VERSION "FA20DIT LF75404S (clean-room, our research notes)"

NS_ :

BS_:

BU_: ECM VDC TCM METER BCM OTHER

BO_ 208 RX_0D0: 8 VDC
 SG_ vdc0d0_b6 : 48|8@1+ (1,0) [0|0] "signed" ECM
 SG_ vdc0d0_b7 : 56|8@1+ (1,0) [0|0] "signed" ECM

BO_ 209 RX_0D1: 4 VDC
 SG_ vehicle_speed : 0|16@1+ (0.05625,0) [0|0] "km/h" ECM
 SG_ brake_pressure : 16|8@1+ (1,0) [0|0] "raw" ECM

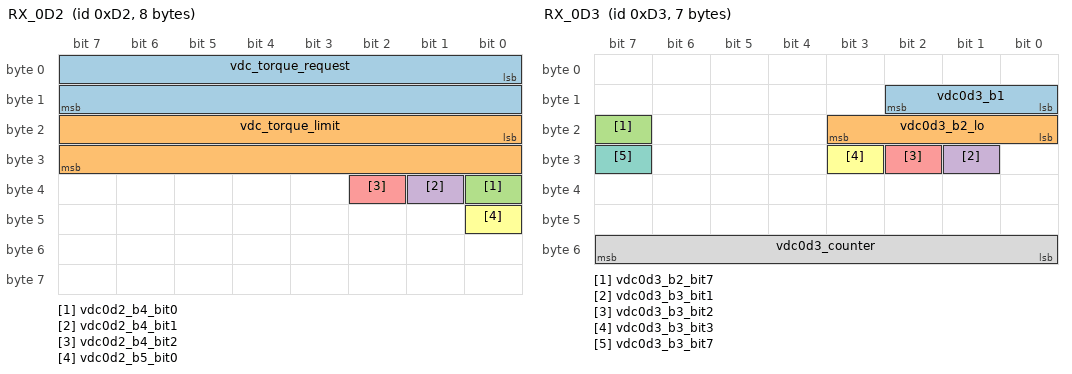
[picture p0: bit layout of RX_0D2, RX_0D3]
BO_ 210 RX_0D2: 8 VDC
 SG_ vdc_torque_request : 0|16@1+ (0.1,-1000) [0|0] "Nm" ECM
 SG_ vdc_torque_limit : 16|16@1+ (0.1,-1000) [0|0] "Nm" ECM
 SG_ vdc0d2_b4_bit0 : 32|1@1+ (1,0) [0|0] "raw" ECM
 SG_ vdc0d2_b4_bit1 : 33|1@1+ (1,0) [0|0] "raw" ECM
 SG_ vdc0d2_b4_bit2 : 34|1@1+ (1,0) [0|0] "raw" ECM
 SG_ vdc0d2_b5_bit0 : 40|1@1+ (1,0) [0|0] "raw" ECM

BO_ 211 RX_0D3: 7 VDC
 SG_ vdc0d3_b1 : 8|3@1+ (1,0) [0|0] "raw" ECM
 SG_ vdc0d3_b2_lo : 16|4@1+ (1,0) [0|0] "raw" ECM
 SG_ vdc0d3_b2_bit7 : 23|1@1+ (1,0) [0|0] "raw" ECM
 SG_ vdc0d3_b3_bit1 : 25|1@1+ (1,0) [0|0] "raw" ECM
 SG_ vdc0d3_b3_bit2 : 26|1@1+ (1,0) [0|0] "raw" ECM
 SG_ vdc0d3_b3_bit3 : 27|1@1+ (1,0) [0|0] "raw" ECM
 SG_ vdc0d3_b3_bit7 : 31|1@1+ (1,0) [0|0] "raw" ECM
 SG_ vdc0d3_counter : 48|8@1+ (1,0) [0|0] "raw" ECM

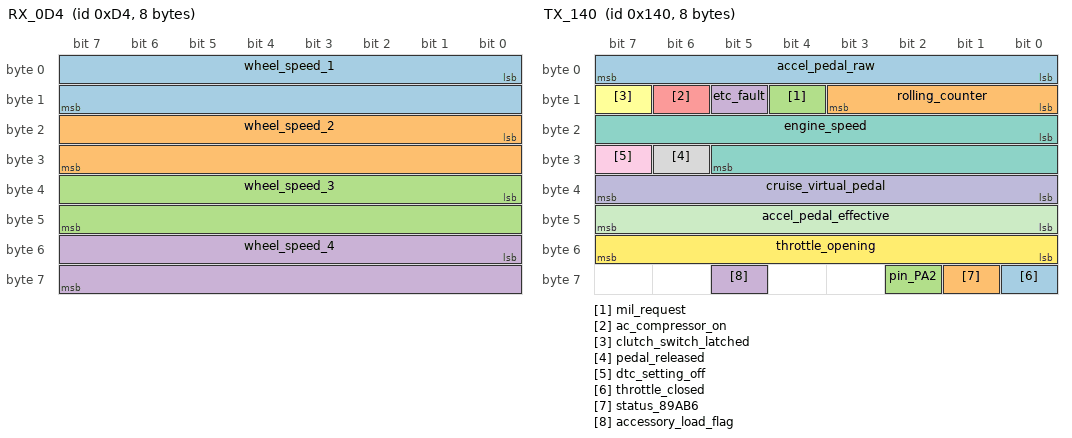
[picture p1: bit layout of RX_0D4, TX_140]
BO_ 212 RX_0D4: 8 VDC
 SG_ wheel_speed_1 : 0|16@1+ (0.05625,0) [0|0] "km/h" ECM
 SG_ wheel_speed_2 : 16|16@1+ (0.05625,0) [0|0] "km/h" ECM
 SG_ wheel_speed_3 : 32|16@1+ (0.05625,0) [0|0] "km/h" ECM
 SG_ wheel_speed_4 : 48|16@1+ (0.05625,0) [0|0] "km/h" ECM

BO_ 320 TX_140: 8 ECM
 SG_ accel_pedal_raw : 0|8@1+ (0.39215686274509803,0) [0|0] "%" Vector__XXX
 SG_ rolling_counter : 8|4@1+ (1,0) [0|0] "count" Vector__XXX
 SG_ mil_request : 12|1@1+ (1,0) [0|0] "flag" Vector__XXX
 SG_ etc_fault : 13|1@1+ (1,0) [0|0] "flag" Vector__XXX
 SG_ ac_compressor_on : 14|1@1+ (1,0) [0|0] "flag" Vector__XXX
 SG_ clutch_switch_latched : 15|1@1+ (1,0) [0|0] "flag" Vector__XXX
 SG_ engine_speed : 16|14@1+ (1,0) [0|0] "rpm" Vector__XXX
 SG_ pedal_released : 30|1@1+ (1,0) [0|0] "flag" Vector__XXX
 SG_ dtc_setting_off : 31|1@1+ (1,0) [0|0] "flag" Vector__XXX
 SG_ cruise_virtual_pedal : 32|8@1+ (0.39215686274509803,0) [0|0] "%" Vector__XXX
 SG_ accel_pedal_effective : 40|8@1+ (0.39215686274509803,0) [0|0] "%" Vector__XXX
 SG_ throttle_opening : 48|8@1+ (0.39215686274509803,0) [0|0] "%" Vector__XXX
 SG_ throttle_closed : 56|1@1+ (1,0) [0|0] "flag" Vector__XXX
 SG_ status_89AB6 : 57|1@1+ (1,0) [0|0] "flag" Vector__XXX
 SG_ pin_PA2 : 58|1@1+ (1,0) [0|0] "flag" Vector__XXX
 SG_ accessory_load_flag : 61|1@1+ (1,0) [0|0] "flag" Vector__XXX

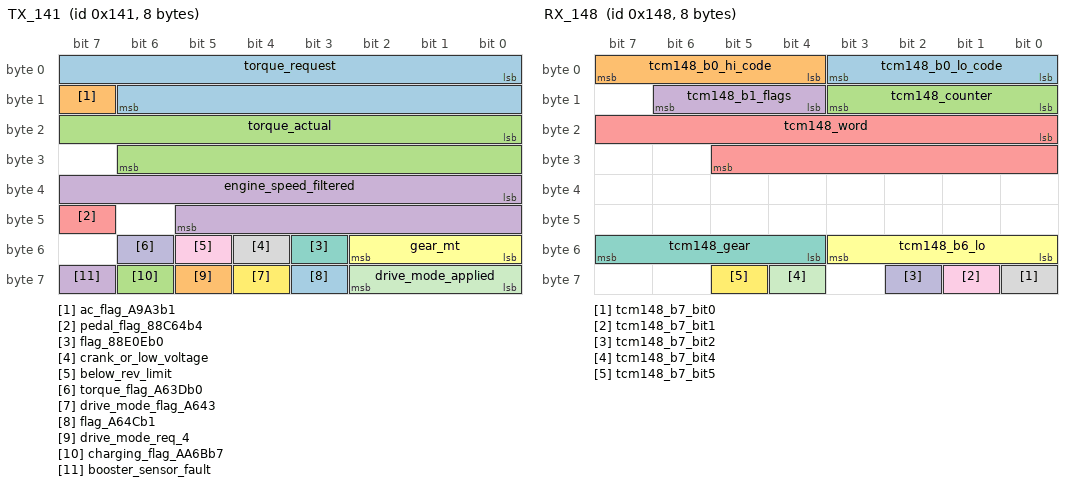
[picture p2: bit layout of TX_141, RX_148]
BO_ 321 TX_141: 8 ECM
 SG_ torque_request : 0|15@1+ (0.1,-1000) [0|0] "Nm" Vector__XXX
 SG_ ac_flag_A9A3b1 : 15|1@1+ (1,0) [0|0] "flag" Vector__XXX
 SG_ torque_actual : 16|15@1+ (0.1,-1000) [0|0] "Nm" Vector__XXX
 SG_ engine_speed_filtered : 32|14@1+ (1,0) [0|0] "rpm" Vector__XXX
 SG_ pedal_flag_88C64b4 : 47|1@1+ (1,0) [0|0] "flag" Vector__XXX
 SG_ gear_mt : 48|3@1+ (1,0) [0|0] "gear" Vector__XXX
 SG_ flag_88E0Eb0 : 51|1@1+ (1,0) [0|0] "flag" Vector__XXX
 SG_ crank_or_low_voltage : 52|1@1+ (1,0) [0|0] "flag" Vector__XXX
 SG_ below_rev_limit : 53|1@1+ (1,0) [0|0] "flag" Vector__XXX
 SG_ torque_flag_A63Db0 : 54|1@1+ (1,0) [0|0] "flag" Vector__XXX
 SG_ drive_mode_applied : 56|3@1+ (1,0) [0|0] "code" Vector__XXX
 SG_ drive_mode_flag_A643 : 60|1@1+ (1,0) [0|0] "flag" Vector__XXX
 SG_ flag_A64Cb1 : 59|1@1+ (1,0) [0|0] "flag" Vector__XXX
 SG_ drive_mode_req_4 : 61|1@1+ (1,0) [0|0] "flag" Vector__XXX
 SG_ charging_flag_AA6Bb7 : 62|1@1+ (1,0) [0|0] "flag" Vector__XXX
 SG_ booster_sensor_fault : 63|1@1+ (1,0) [0|0] "flag" Vector__XXX

BO_ 324 TX_144: 8 ECM
 SG_ cruise_switch_flag : 2|1@1+ (1,0) [0|0] "flag" Vector__XXX
 SG_ cruise_switch_code : 3|3@1+ (1,0) [0|0] "code" Vector__XXX
 SG_ cruise_meter_flag_b5 : 6|1@1+ (1,0) [0|0] "flag" Vector__XXX
 SG_ cruise_meter_flag_b6 : 7|1@1+ (1,0) [0|0] "flag" Vector__XXX
 SG_ drive_cycle_done : 9|1@1+ (1,0) [0|0] "flag" Vector__XXX
 SG_ torque_monitor_AC77b0 : 11|1@1+ (1,0) [0|0] "flag" Vector__XXX
 SG_ cruise_switch_taps : 12|4@1+ (1,0) [0|0] "bits" Vector__XXX
 SG_ max_available_torque : 16|8@1+ (1.6,0) [0|0] "Nm" Vector__XXX
 SG_ start_counter : 24|8@1+ (1,0) [0|0] "count" Vector__XXX
 SG_ warmup_counter : 32|8@1+ (1,0) [0|0] "count" Vector__XXX
 SG_ coding_byte : 40|8@1+ (1,0) [0|0] "raw" Vector__XXX
 SG_ cruise_standby : 48|1@1+ (1,0) [0|0] "flag" Vector__XXX
 SG_ cruise_active : 49|1@1+ (1,0) [0|0] "flag" Vector__XXX
 SG_ cruise_override : 50|1@1+ (1,0) [0|0] "flag" Vector__XXX
 SG_ pin_PA15 : 51|1@1+ (1,0) [0|0] "flag" Vector__XXX
 SG_ can_fault_latch : 52|1@1+ (1,0) [0|0] "flag" Vector__XXX
 SG_ cruise_unavailable : 53|1@1+ (1,0) [0|0] "flag" Vector__XXX
 SG_ vdc_flag_inverted : 54|1@1+ (1,0) [0|0] "flag" Vector__XXX
 SG_ mt_coding : 55|1@1+ (1,0) [0|0] "flag" Vector__XXX
 SG_ drive_mode_state : 56|1@1+ (1,0) [0|0] "flag" Vector__XXX
 SG_ drive_mode_requested : 57|3@1+ (1,0) [0|0] "code" Vector__XXX
 SG_ cal_57ABC_b2 : 62|1@1+ (1,0) [0|0] "flag" Vector__XXX

BO_ 328 RX_148: 8 TCM
 SG_ tcm148_b0_lo_code : 0|4@1+ (1,0) [0|0] "raw" ECM
 SG_ tcm148_b0_hi_code : 4|4@1+ (1,0) [0|0] "raw" ECM
 SG_ tcm148_counter : 8|4@1+ (1,0) [0|0] "raw" ECM
 SG_ tcm148_b1_flags : 12|3@1+ (1,0) [0|0] "raw" ECM
 SG_ tcm148_word : 16|14@1+ (1,0) [0|0] "raw" ECM
 SG_ tcm148_b6_lo : 48|4@1+ (1,0) [0|0] "raw" ECM
 SG_ tcm148_gear : 52|4@1+ (1,0) [0|0] "gear code" ECM
 SG_ tcm148_b7_bit0 : 56|1@1+ (1,0) [0|0] "raw" ECM
 SG_ tcm148_b7_bit1 : 57|1@1+ (1,0) [0|0] "raw" ECM
 SG_ tcm148_b7_bit2 : 58|1@1+ (1,0) [0|0] "raw" ECM
 SG_ tcm148_b7_bit4 : 60|1@1+ (1,0) [0|0] "raw" ECM
 SG_ tcm148_b7_bit5 : 61|1@1+ (1,0) [0|0] "raw" ECM

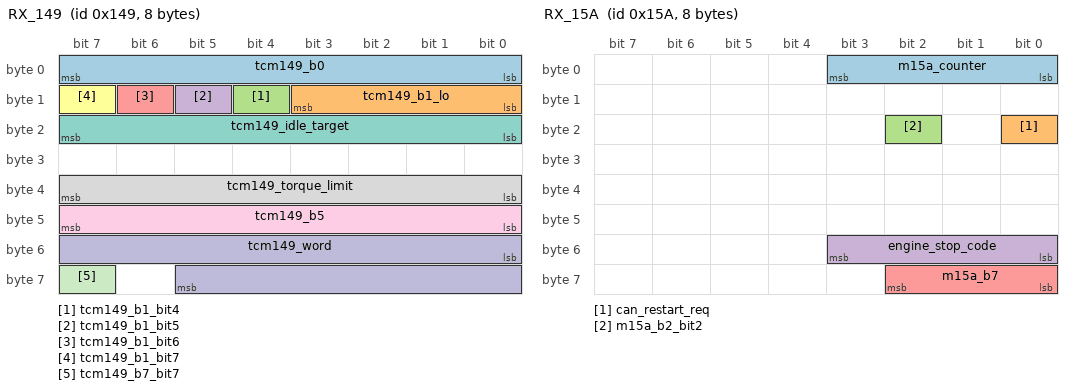
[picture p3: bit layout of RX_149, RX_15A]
BO_ 329 RX_149: 8 TCM
 SG_ tcm149_b0 : 0|8@1+ (1,0) [0|0] "raw" ECM
 SG_ tcm149_b1_lo : 8|4@1+ (1,0) [0|0] "raw" ECM
 SG_ tcm149_b1_bit4 : 12|1@1+ (1,0) [0|0] "raw" ECM
 SG_ tcm149_b1_bit5 : 13|1@1+ (1,0) [0|0] "raw" ECM
 SG_ tcm149_b1_bit6 : 14|1@1+ (1,0) [0|0] "raw" ECM
 SG_ tcm149_b1_bit7 : 15|1@1+ (1,0) [0|0] "raw" ECM
 SG_ tcm149_idle_target : 16|8@1+ (8,0) [0|0] "rpm" ECM
 SG_ tcm149_torque_limit : 32|8@1+ (2,0) [0|0] "Nm" ECM
 SG_ tcm149_b5 : 40|8@1+ (1,0) [0|0] "raw" ECM
 SG_ tcm149_word : 48|14@1+ (1,0) [0|0] "raw" ECM
 SG_ tcm149_b7_bit7 : 63|1@1+ (1,0) [0|0] "raw" ECM

BO_ 338 RX_152: 8 BCM
 SG_ bcm152_b1_bit0 : 8|1@1+ (1,0) [0|0] "raw" ECM
 SG_ bcm152_b1_bit1 : 9|1@1+ (1,0) [0|0] "raw" ECM
 SG_ bcm152_b1_bit2 : 10|1@1+ (1,0) [0|0] "raw" ECM
 SG_ bcm152_b1_bit3 : 11|1@1+ (1,0) [0|0] "raw" ECM
 SG_ bcm152_counter : 12|4@1+ (1,0) [0|0] "raw" ECM
 SG_ bcm152_b6_bit0 : 48|1@1+ (1,0) [0|0] "raw" ECM
 SG_ bcm152_b6_bit2 : 50|1@1+ (1,0) [0|0] "raw" ECM
 SG_ bcm152_b6_bit3 : 51|1@1+ (1,0) [0|0] "raw" ECM
 SG_ bcm152_b6_bit4 : 52|1@1+ (1,0) [0|0] "raw" ECM
 SG_ bcm152_b6_bit5 : 53|1@1+ (1,0) [0|0] "raw" ECM
 SG_ bcm152_b6_hi : 54|2@1+ (1,0) [0|0] "raw" ECM
 SG_ bcm152_b7_bit1 : 57|1@1+ (1,0) [0|0] "raw" ECM
 SG_ bcm152_b7_bit2 : 58|1@1+ (1,0) [0|0] "raw" ECM
 SG_ bcm152_b7_bit3 : 59|1@1+ (1,0) [0|0] "raw" ECM
 SG_ bcm152_b7_bit4 : 60|1@1+ (1,0) [0|0] "raw" ECM
 SG_ bcm152_b7_bit5 : 61|1@1+ (1,0) [0|0] "raw" ECM
 SG_ bcm152_b7_bit6 : 62|1@1+ (1,0) [0|0] "raw" ECM
 SG_ bcm152_b7_bit7 : 63|1@1+ (1,0) [0|0] "raw" ECM

BO_ 346 RX_15A: 8 OTHER
 SG_ m15a_counter : 0|4@1+ (1,0) [0|0] "raw" ECM
 SG_ can_restart_req : 16|1@1+ (1,0) [0|0] "raw" ECM
 SG_ m15a_b2_bit2 : 18|1@1+ (1,0) [0|0] "raw" ECM
 SG_ engine_stop_code : 48|4@1+ (1,0) [0|0] "raw" ECM
 SG_ m15a_b7 : 56|3@1+ (1,0) [0|0] "raw" ECM

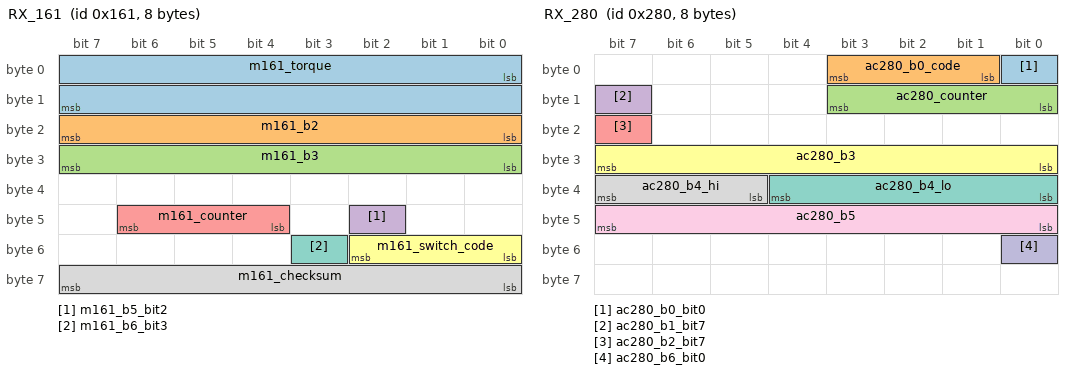
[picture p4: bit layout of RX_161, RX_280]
BO_ 353 RX_161: 8 METER
 SG_ m161_torque : 0|16@1+ (0.1,-1000) [0|0] "Nm" ECM
 SG_ m161_b2 : 16|8@1+ (1,0) [0|0] "raw" ECM
 SG_ m161_b3 : 24|8@1+ (1,0) [0|0] "raw" ECM
 SG_ m161_b5_bit2 : 42|1@1+ (1,0) [0|0] "raw" ECM
 SG_ m161_counter : 44|3@1+ (1,0) [0|0] "raw" ECM
 SG_ m161_switch_code : 48|3@1+ (1,0) [0|0] "raw" ECM
 SG_ m161_b6_bit3 : 51|1@1+ (1,0) [0|0] "raw" ECM
 SG_ m161_checksum : 56|8@1+ (1,0) [0|0] "raw" ECM

BO_ 392 RX_188: 8 OTHER
 SG_ m188_counter : 17|3@1+ (1,0) [0|0] "raw" ECM
 SG_ m188_code : 32|3@1+ (1,0) [0|0] "raw" ECM

BO_ 640 RX_280: 8 OTHER
 SG_ ac280_b0_bit0 : 0|1@1+ (1,0) [0|0] "raw" ECM
 SG_ ac280_b0_code : 1|3@1+ (1,0) [0|0] "raw" ECM
 SG_ ac280_counter : 8|4@1+ (1,0) [0|0] "raw" ECM
 SG_ ac280_b1_bit7 : 15|1@1+ (1,0) [0|0] "raw" ECM
 SG_ ac280_b2_bit7 : 23|1@1+ (1,0) [0|0] "raw" ECM
 SG_ ac280_b3 : 24|8@1+ (1,0) [0|0] "raw" ECM
 SG_ ac280_b4_lo : 32|5@1+ (1,0) [0|0] "raw" ECM
 SG_ ac280_b4_hi : 37|3@1+ (1,0) [0|0] "raw" ECM
 SG_ ac280_b5 : 40|8@1+ (1,0) [0|0] "%" ECM
 SG_ ac280_b6_bit0 : 48|1@1+ (1,0) [0|0] "raw" ECM

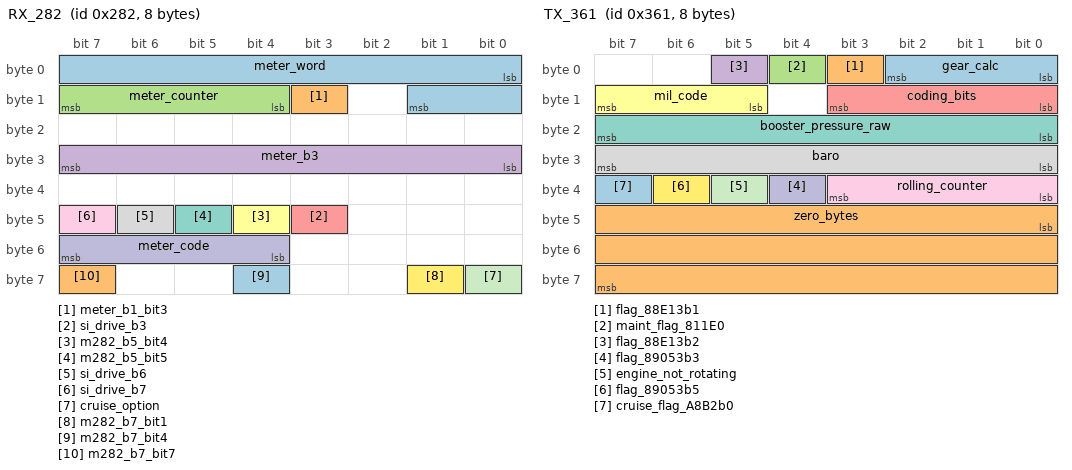
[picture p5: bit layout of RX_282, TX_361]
BO_ 642 RX_282: 8 METER
 SG_ meter_word : 0|10@1+ (1,0) [0|0] "raw" ECM
 SG_ meter_b1_bit3 : 11|1@1+ (1,0) [0|0] "raw" ECM
 SG_ meter_counter : 12|4@1+ (1,0) [0|0] "raw" ECM
 SG_ meter_b3 : 24|8@1+ (1,0) [0|0] "raw" ECM
 SG_ si_drive_b3 : 43|1@1+ (1,0) [0|0] "raw" ECM
 SG_ m282_b5_bit4 : 44|1@1+ (1,0) [0|0] "raw" ECM
 SG_ m282_b5_bit5 : 45|1@1+ (1,0) [0|0] "raw" ECM
 SG_ si_drive_b6 : 46|1@1+ (1,0) [0|0] "raw" ECM
 SG_ si_drive_b7 : 47|1@1+ (1,0) [0|0] "raw" ECM
 SG_ meter_code : 52|4@1+ (1,0) [0|0] "raw" ECM
 SG_ cruise_option : 56|1@1+ (1,0) [0|0] "raw" ECM
 SG_ m282_b7_bit1 : 57|1@1+ (1,0) [0|0] "raw" ECM
 SG_ m282_b7_bit4 : 60|1@1+ (1,0) [0|0] "raw" ECM
 SG_ m282_b7_bit7 : 63|1@1+ (1,0) [0|0] "raw" ECM

BO_ 864 TX_360: 8 ECM
 SG_ fuel_flow : 0|16@1+ (0.001,0) [0|0] "unit not settled" Vector__XXX
 SG_ oil_temp : 16|8@1+ (1,-40) [0|0] "degC" Vector__XXX
 SG_ coolant_temp : 24|8@1+ (1,-40) [0|0] "degC" Vector__XXX
 SG_ map : 32|8@1+ (2,0) [0|0] "kPa abs" Vector__XXX
 SG_ flag_888A7b1 : 40|1@1+ (1,0) [0|0] "flag" Vector__XXX
 SG_ drive_mode_req_bits : 41|3@1+ (1,0) [0|0] "code" Vector__XXX
 SG_ cruise_lamp_main : 44|1@1+ (1,0) [0|0] "flag" Vector__XXX
 SG_ cruise_lamp_set : 45|1@1+ (1,0) [0|0] "flag" Vector__XXX
 SG_ engine_warm_latch : 46|1@1+ (1,0) [0|0] "flag" Vector__XXX
 SG_ flag_ACECb4 : 47|1@1+ (1,0) [0|0] "flag" Vector__XXX
 SG_ flag_88E14b0 : 48|1@1+ (1,0) [0|0] "flag" Vector__XXX
 SG_ elec_load_flag : 49|1@1+ (1,0) [0|0] "flag" Vector__XXX
 SG_ flag_88E14b4 : 50|1@1+ (1,0) [0|0] "flag" Vector__XXX
 SG_ flag_8889Eb5 : 51|1@1+ (1,0) [0|0] "flag" Vector__XXX
 SG_ rad_fan_1 : 52|1@1+ (1,0) [0|0] "flag" Vector__XXX
 SG_ rad_fan_2 : 53|1@1+ (1,0) [0|0] "flag" Vector__XXX
 SG_ ac_switch_PA8 : 54|1@1+ (1,0) [0|0] "flag" Vector__XXX
 SG_ ac_request : 55|1@1+ (1,0) [0|0] "flag" Vector__XXX
 SG_ cruise_set_speed : 56|8@1+ (1,0) [0|0] "km/h or mph" Vector__XXX

BO_ 865 TX_361: 8 ECM
 SG_ gear_calc : 0|3@1+ (1,0) [0|0] "gear" Vector__XXX
 SG_ flag_88E13b1 : 3|1@1+ (1,0) [0|0] "flag" Vector__XXX
 SG_ maint_flag_811E0 : 4|1@1+ (1,0) [0|0] "flag" Vector__XXX
 SG_ flag_88E13b2 : 5|1@1+ (1,0) [0|0] "flag" Vector__XXX
 SG_ coding_bits : 8|4@1+ (1,0) [0|0] "raw" Vector__XXX
 SG_ mil_code : 13|3@1+ (1,0) [0|0] "code" Vector__XXX
 SG_ booster_pressure_raw : 16|8@1+ (256,0) [0|0] "ADC raw" Vector__XXX
 SG_ baro : 24|8@1+ (0.4,13.2) [0|0] "kPa abs" Vector__XXX
 SG_ rolling_counter : 32|4@1+ (1,0) [0|0] "count" Vector__XXX
 SG_ flag_89053b3 : 36|1@1+ (1,0) [0|0] "flag" Vector__XXX
 SG_ engine_not_rotating : 37|1@1+ (1,0) [0|0] "flag" Vector__XXX
 SG_ flag_89053b5 : 38|1@1+ (1,0) [0|0] "flag" Vector__XXX
 SG_ cruise_flag_A8B2b0 : 39|1@1+ (1,0) [0|0] "flag" Vector__XXX
 SG_ zero_bytes : 40|24@1+ (1,0) [0|0] "-" Vector__XXX

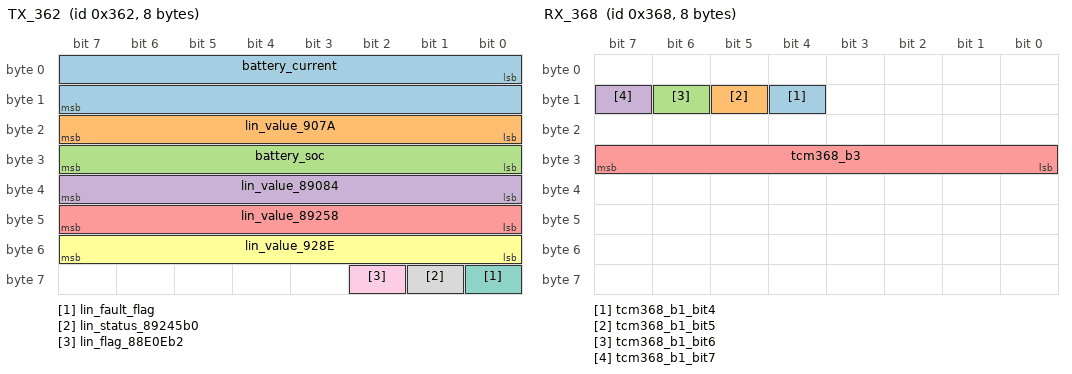
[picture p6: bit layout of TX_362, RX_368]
BO_ 866 TX_362: 8 ECM
 SG_ battery_current : 0|16@1+ (0.004,-125) [0|0] "A" Vector__XXX
 SG_ lin_value_907A : 16|8@1+ (1,0) [0|0] "raw" Vector__XXX
 SG_ battery_soc : 24|8@1+ (0.5,0) [0|0] "%" Vector__XXX
 SG_ lin_value_89084 : 32|8@1+ (8,0) [0|0] "raw" Vector__XXX
 SG_ lin_value_89258 : 40|8@1+ (8,0) [0|0] "raw" Vector__XXX
 SG_ lin_value_928E : 48|8@1+ (64,0) [0|0] "raw" Vector__XXX
 SG_ lin_fault_flag : 56|1@1+ (1,0) [0|0] "flag" Vector__XXX
 SG_ lin_status_89245b0 : 57|1@1+ (1,0) [0|0] "flag" Vector__XXX
 SG_ lin_flag_88E0Eb2 : 58|1@1+ (1,0) [0|0] "flag" Vector__XXX

BO_ 872 RX_368: 8 TCM
 SG_ tcm368_b1_bit4 : 12|1@1+ (1,0) [0|0] "raw" ECM
 SG_ tcm368_b1_bit5 : 13|1@1+ (1,0) [0|0] "raw" ECM
 SG_ tcm368_b1_bit6 : 14|1@1+ (1,0) [0|0] "raw" ECM
 SG_ tcm368_b1_bit7 : 15|1@1+ (1,0) [0|0] "raw" ECM
 SG_ tcm368_b3 : 24|8@1+ (1,0) [0|0] "raw" ECM

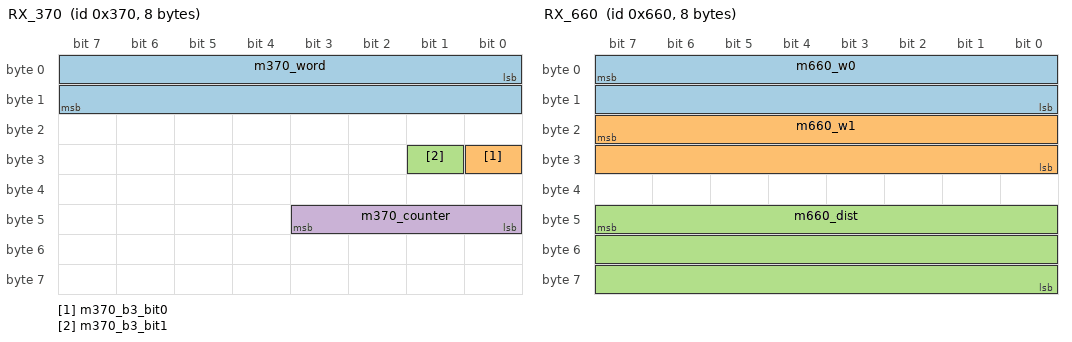
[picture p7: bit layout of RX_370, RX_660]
BO_ 880 RX_370: 8 OTHER
 SG_ m370_word : 0|16@1+ (1,0) [0|0] "raw" ECM
 SG_ m370_b3_bit0 : 24|1@1+ (1,0) [0|0] "raw" ECM
 SG_ m370_b3_bit1 : 25|1@1+ (1,0) [0|0] "raw" ECM
 SG_ m370_counter : 40|4@1+ (1,0) [0|0] "raw" ECM

BO_ 882 RX_372: 8 OTHER
 SG_ m372_counter : 12|4@1+ (1,0) [0|0] "raw" ECM
 SG_ m372_code : 21|3@1+ (1,0) [0|0] "raw" ECM

BO_ 977 RX_3D1: 8 METER
 SG_ ambient_temp_raw : 0|13@1+ (1,0) [0|0] "raw" ECM

BO_ 1632 RX_660: 8 BCM
 SG_ m660_w0 : 7|16@0+ (1,0) [0|0] "raw" ECM
 SG_ m660_w1 : 23|16@0+ (1,0) [0|0] "raw" ECM
 SG_ m660_dist : 47|24@0+ (1,0) [0|0] "raw" ECM

BO_ 1905 TX_771: 8 ECM
 SG_ periodic_did : 0|8@1+ (1,0) [0|0] "DID low byte (0xF2xx)" Vector__XXX
 SG_ did_data : 8|56@1+ (1,0) [0|0] "raw" Vector__XXX

BO_ 2015 RX_7DF: 8 OTHER

BO_ 2016 RX_7E0: 8 OTHER

BO_ 2024 TX_7E8: 8 ECM

CM_ SG_ 208 vdc0d0_b6 "RAM FFF88DF7; inferred; -> 0x11637C (gated by cal 0x364F3 b6) -> FFF8A8D1 / B406 / B452; meaning not determined";
CM_ SG_ 208 vdc0d0_b7 "RAM FFF88DF8; inferred; as byte 6";
CM_ BO_ 208 "VDC (FFF88DD8, U0122); timeout 30 ms";
CM_ SG_ 209 vehicle_speed "RAM FFF88E18; read; -> 0x118D9C -> FFF8B4C2 -> 0x06C21C -> FFF88BE8 (ECU vehicle speed, x17.78) and FFF99835 (km/h); fallback 10 km/h on VDC fault";
CM_ SG_ 209 brake_pressure "RAM FFF88DF9; inferred; brake override 0x181B38 (FFF8AC94), 0x0DE0E0, 0x0EE338, 0x111AB8";
CM_ BO_ 209 "VDC (FFF88DD8); timeout 30 ms";
CM_ SG_ 210 vdc_torque_request "RAM FFF888B4; inferred; -> 0x116264 -> FFF8B470 (applied only while FFF8A89F b2 = byte4 bit1 and value > 10000 and FFF886AB b5); fallback 10000 (0 Nm)";
CM_ SG_ 210 vdc_torque_limit "RAM FFF888B6; inferred; -> 0x117778 -> FFF8B47C/B464/B466 (torque module 0x0BE694, monitors 0x189DF0/0x1A8D6C); fallback 0x3700 (+408 Nm)";
CM_ SG_ 210 vdc0d2_b4_bit0 "RAM FFF88B94 b0; read; 0x117778 select, 0x11B594 -> FFF8A89F b3";
CM_ SG_ 210 vdc0d2_b4_bit1 "RAM FFF88B93 b1; read; torque-request enable (0x11B814 -> FFF8A89F b2)";
CM_ SG_ 210 vdc0d2_b4_bit2 "RAM FFF88B93 b2; read; 0x1191D4 -> FFF8A89F b1";
CM_ SG_ 210 vdc0d2_b5_bit0 "RAM FFF88B93 b3; read; 0x115438 (SI-Drive arbitration), 0x0BE694";
CM_ BO_ 210 "VDC (FFF88DD8); timeout 30 ms";
CM_ SG_ 211 vdc0d3_b1 "RAM FFF88B95 b0-2; read; b0/b1 -> 0x11BBB4 -> FFF8A898, FFF8A8A1 b7";
CM_ SG_ 211 vdc0d3_b2_lo "RAM FFF88B96 b0-3; read; 0x1191D4, 0x11A0C4 (FFF8A8A2 b7), 0x11FA38";
CM_ SG_ 211 vdc0d3_b2_bit7 "RAM FFF88B97 b6; read; brake override validity 0x181978";
CM_ SG_ 211 vdc0d3_b3_bit1 "RAM FFF88B94 b7; read; 0x113894 (FFF8A8D1 path)";
CM_ SG_ 211 vdc0d3_b3_bit2 "RAM FFF88B94 b2; read; speed/VDC status: 0x06EDDC, cruise speed 0x16C2D0";
CM_ SG_ 211 vdc0d3_b3_bit3 "RAM FFF88B97 b3; read; 0x115438 SI-Drive, brake override 0x181978";
CM_ SG_ 211 vdc0d3_b3_bit7 "RAM FFF88B97 b7; read; 0x11BD48 -> FFF8A89F b0; FFF9BA24..26 delay line (0x0B5758)";
CM_ SG_ 211 vdc0d3_counter "RAM FFF888BB; read; rolling counter; U0416 if unchanged 200 passes";
CM_ BO_ 211 "VDC (FFF88DD8; U0416 = this counter frozen); timeout 30 ms; counter byte6 (whole byte, frozen check)";
CM_ SG_ 212 wheel_speed_1 "RAM FFF88B98; inferred; -> FFF8B4C0";
CM_ SG_ 212 wheel_speed_2 "RAM FFF88B9A; inferred; -> FFF8B4C4";
CM_ SG_ 212 wheel_speed_3 "RAM FFF88B9C; inferred; -> FFF8B4C6";
CM_ SG_ 212 wheel_speed_4 "RAM FFF88B9E; inferred; -> FFF8B4C8";
CM_ BO_ 212 "VDC (FFF88DD8); timeout 30 ms";
CM_ SG_ 320 accel_pedal_raw "RAM FFF8A8D8 <- hi(FFF88EE8); read/inferred; Accelerator pedal, channel-1 position through Accelerator Pedal Scaling (0..65535) high byte; fallback cal 0x573C4 on pedal fault";
CM_ SG_ 320 rolling_counter "RAM FFF8A893; read; 4-bit rolling counter 0..15, +1 per 10 ms (= per frame); 0..7 in variants 0";
CM_ SG_ 320 mil_request "RAM FFF88E13 b0; read/inferred; MIL requested: FFF99809 b3 (DTC confirmed, MIL on) OR FFF88E69 b1 (flashing-MIL DTC)";
CM_ SG_ 320 etc_fault "RAM FFF88EDA b4; read/inferred; Copy of FFF8A2B8 b7: electronic-throttle fault with motor drive off (Phase 13 TE)";
CM_ SG_ 320 ac_compressor_on "RAM FFF8A9A2 b7; inferred; A/C compressor output engaged (A/C module 0x121B90)";
CM_ SG_ 320 clutch_switch_latched "RAM FFF88E62 b0; inferred; MT only: FFF88E62 b1 (pin PA14, active low) latched while MT coding FFF88ADA b7, released after cal 0x5780F passes; clutch pedal switch (inferred)";
CM_ SG_ 320 engine_speed "RAM FFF8B438 = FFF8CD54 x 50/256; read; Engine speed, 1 rpm/bit (CD54 = rpm x 5.12), 14 bits";
CM_ SG_ 320 pedal_released "RAM FFF88C64 b5; read; Accelerator fully released (0x09FF9A, Phase 11 A)";
CM_ SG_ 320 dtc_setting_off "RAM FFF99A7C b5; read; Set by UDS 0x85 ControlDTCSetting 0x02 (off) in session 2/3 (0x0B54AC); cleared at reset/0x0B7730";
CM_ SG_ 320 cruise_virtual_pedal "RAM FFF8A896 <- hi(FFF8B9AC); inferred; Cruise module pedal-equivalent request (B9AC, written by 0x168864); 0 when not cruising";
CM_ SG_ 320 accel_pedal_effective "RAM FFF8A8EC <- hi(FFF8AF00); read; Pedal used by the torque request: FFF88A5E, or max(pedal, B9AC) while cruise (FFF88E12 b1)";
CM_ SG_ 320 throttle_opening "RAM FFF8A8E8 = FFF888A4/100; inferred; Throttle opening: 888A4 = FFF88A3A x 25600 / cal 0x35AFE (43515); 255 ~ 100 % (scale inferred)";
CM_ SG_ 320 throttle_closed "RAM FFF88E14 b7; read; Throttle byte FFF8CD77 <= cal 0x3550C (3), +cal 0x3550D (2) hysteresis: throttle (nearly) closed";
CM_ SG_ 320 status_89AB6 "RAM FFF888A7 b6; unknown; FFF89AB6 != 0; 89AB6 set/cleared by a serial handshake in 0x090E8A/0x09203A (not decoded)";
CM_ SG_ 320 pin_PA2 "RAM FFF8A291 b4; read (meaning unknown); Raw discrete input A29A b4 = pin PA2 (active low) masked by cal 0x5693A (=0)";
CM_ SG_ 320 accessory_load_flag "RAM FFF88E2E b6; read/inferred; FFF8A8A0 b0, or (coding FFF811DC != 0x5A) input FFF88BC6 b4 (pin PA4); the flag that enables Idle Air Adder (CAN 0x280 Stage)";
CM_ BO_ 320 "period 10 ms";
CM_ SG_ 321 torque_request "RAM FFF8B462; read/inferred; Driver torque request after the external limit (AEA6) x AEA0 (=1.0 stock): 10000 + 10 x Nm; with the pedal released: 10000 - 10 x friction (B46C)";
CM_ SG_ 321 ac_flag_A9A3b1 "RAM FFF8A9A3 b1; unknown; A/C module 0x121B90 output bit (not decoded)";
CM_ SG_ 321 torque_actual "RAM FFF8B404; inferred; Estimated engine torque: DAM-weighted torque-from-load (B490/B4A2) through 05D3D8/05D3E4, minus losses AF62 and an idle term; 10000 + 10 x Nm, floor 0";
CM_ SG_ 321 engine_speed_filtered "RAM FFF8B740; inferred; Filtered engine speed (CE9C, weight B73E); with an AT it tracks the TCM speed FFF8924E (0x149); 0 when FFF88A28 b1 clear or engine not rotating";
CM_ SG_ 321 pedal_flag_88C64b4 "RAM FFF8A8A9 b1 <- FFF88C64 b4; unknown; Copy of FFF88C64 b4 (pedal module 0x09F282, not decoded)";
CM_ SG_ 321 gear_mt "RAM FFF8A8AA b0-2 <- FFF88FCE; read; Gear 1..6 as binary; 7 when neutral (FFF88ADA b6); hold otherwise; 0 when not MT";
CM_ SG_ 321 flag_88E0Eb0 "RAM FFF88E0E b0; unknown; From 88A27 b0, 88ADA b3, 89010 b0, module voltage 88A7E, coolant 88A44, A82E b7";
CM_ SG_ 321 crank_or_low_voltage "RAM FFF8889F b2; inferred; 0 only when 88A27 b0 and 88ADA b3 clear, module voltage FFF88A7E > 0x6666 and a start timer (cal 0x35B06) expired";
CM_ SG_ 321 below_rev_limit "RAM FFF888A2 b2; inferred; rpm < AED4 + cal 0x3552C and (rpm < A62E x 128 + cal 0x3552E or A63D b0 clear)";
CM_ SG_ 321 torque_flag_A63Db0 "RAM FFF8A63D b0; unknown; Torque module 0x0BE694 status bit";
CM_ SG_ 321 drive_mode_applied "RAM FFF8A8AB b0-2 <- FFF8A8C3; read; SI-Drive mode applied (A8C3): mode1 (default) -> b1b0=11, mode2 (Sport) -> b0, mode3 (Intelligent) -> b1, mode4 (Sport Sharp) -> b2; positions inferred from the stock maps (Phase 22)";
CM_ SG_ 321 drive_mode_flag_A643 "RAM FFF88E10 b6; read (meaning unknown); FFF8A643 in {1,2,3}";
CM_ SG_ 321 flag_A64Cb1 "RAM FFF88E10 b7 <- FFF8A64C b1; unknown; copy";
CM_ SG_ 321 drive_mode_req_4 "RAM FFF8A8AF b0; read; Last accepted requested mode A8C2 == 4";
CM_ SG_ 321 charging_flag_AA6Bb7 "RAM FFF8AA6B b7; unknown; Charging-control module 0x13741C status bit (sent while cal 0x57584 b4 = 0)";
CM_ SG_ 321 booster_sensor_fault "RAM FFF88E2B b6 <- FFF89CF3 b2; read/inferred; Brake-booster pressure sensor FFF88D0C out of range low/high (0x071B82, cal 0x57585 b5)";
CM_ BO_ 321 "period 10 ms";
CM_ SG_ 324 cruise_switch_flag "RAM FFF88E10 b2; unknown; Cruise switch decoder 0x08DF14 bit";
CM_ SG_ 324 cruise_switch_code "RAM FFF8A8AC b3-5; read/inferred; Cruise lever switches FFF88EC9 b0/b1/b3/b2 one-hot-ish: b3 = b0 or b3 alone, b4 = b1 or b3 alone, b5 = b2 alone (held otherwise)";
CM_ SG_ 324 cruise_meter_flag_b5 "RAM FFF8A8A9 b5; inferred; Cruise module 0x16557C (0x16EC9C), meter-related cruise state";
CM_ SG_ 324 cruise_meter_flag_b6 "RAM FFF8A8A9 b6; inferred; Cruise module 0x16557C (0x16EE1C)";
CM_ SG_ 324 drive_cycle_done "RAM FFF89D39 b0; inferred; Set once counters 89D3A >= 600, 89D3C >= 300, 89D3E >= 30 (OBD driving-cycle criteria, inferred)";
CM_ SG_ 324 torque_monitor_AC77b0 "RAM FFF8AC77 b0; unknown; 0x17B0E8/0x17B268";
CM_ SG_ 324 cruise_switch_taps "RAM FFF88E11 b4-7; inferred; Cruise: b4 raise-switch tap, b5 raise edge, b6 lower-switch tap, b7 lower edge (Phase 18 C)";
CM_ SG_ 324 max_available_torque "RAM FFF8A89C; read/inferred; (T_CAN - friction) x 0.625: T_CAN = Engine Torque from Load (CAN, DAM 1.0/0) blended by DAM; 255 = saturated";
CM_ SG_ 324 start_counter "RAM FFF811DD; inferred; Backup-RAM 8-bit wrap counter, +1 on each rising edge of FFF8AB8C b0 (engine-start event, 0x1739C8) in normal mode (AC78 = 0)";
CM_ SG_ 324 warmup_counter "RAM FFF811DE; inferred; Same for FFF8AB8D b0 (coolant-based event, 0x1739F4): warm-up cycle counter (inferred)";
CM_ SG_ 324 coding_byte "RAM FFF8A8AD <- cal 0x58B7A; read; Bit-permuted copy of cal 0x58B7A (0x0A) -> 0x24 constant on this ROM";
CM_ SG_ 324 cruise_standby "RAM FFF88E12 b0; inferred; Cruise ready/standby (0x16F194)";
CM_ SG_ 324 cruise_active "RAM FFF88E12 b1; read; Cruise controlling (max(pedal torque, cruise torque) used)";
CM_ SG_ 324 cruise_override "RAM FFF88E12 b5; inferred; Driver torque above cruise torque (0x16D1B4)";
CM_ SG_ 324 pin_PA15 "RAM FFF88E12 b4 <- FFF88E2F b5; read (meaning unknown); Discrete pin PA15 (A298.2)";
CM_ SG_ 324 can_fault_latch "RAM FFF88E13 b4; read/inferred; Latched (until reset) when 88DD4 b4/b5/b6 (0x161 group U-codes) or A8A4 b3/b5";
CM_ SG_ 324 cruise_unavailable "RAM FFF8A8B2 b4; inferred; 0 only when meter flags 811E1 b4 and b2 set and no fault (88BB2 b0, 88E13 b4/b0, A8A4 b1)";
CM_ SG_ 324 vdc_flag_inverted "RAM NOT FFF88E13 b3; unknown; Inverted output of 0x11B5A4 (inputs incl. VDC request 888B6, MAP, coolant)";
CM_ SG_ 324 mt_coding "RAM FFF8A8AE b7 <- FFF886AB b7; read; Manual-transmission coding (1 on this car)";
CM_ SG_ 324 drive_mode_state "RAM FFF8A8AF b3; read; Drive-mode state machine A8C0 in {2,3,4,5}";
CM_ SG_ 324 drive_mode_requested "RAM FFF8A8AF b1,b2,b0; read; Requested/accepted mode A8C2: bit1 = A8C2 in {1,2}, bit2 = in {1,3}, bit3 = (A8C2 == 4)";
CM_ SG_ 324 cal_57ABC_b2 "RAM FFF88E0E b3; read; Copy of cal 0x57ABC b2 (0 -> always 0)";
CM_ BO_ 324 "period 20 ms";
CM_ SG_ 328 tcm148_b0_lo_code "RAM FFF88B87 b4-7; read; -> 0x1174EC -> FFF8A8DC (code map 0000->8, 0001->0, 0010->1, 0011->2, 0100->3, 1010->4, 1011->5, 1100->6, 1110->7, else hold); range/position-like (inferred)";
CM_ SG_ 328 tcm148_b0_hi_code "RAM FFF88B87 b0-3; read; -> 0x114304 -> FFF8A8B9 (0..8, latched on fresh frame) -> 0x083052";
CM_ SG_ 328 tcm148_counter "RAM FFF888B0; read; rolling counter, frozen-counter check 0x0683EE / U0402 0x078A92";
CM_ SG_ 328 tcm148_b1_flags "RAM FFF88B86 b0-2; read; -> 0x1197E4 -> FFF8A8A1 b6";
CM_ SG_ 328 tcm148_word "RAM FFF888AC; read; consumers 0x094218, 0x0EE338 (idle)";
CM_ SG_ 328 tcm148_b6_lo "RAM FFF88B81 b4-7; read; -> 0x117B18 -> FFF8A8E5 -> 0x116378 -> FFF8A8D0 (0x0C589C, 0x0EE338) and 0x121B90";
CM_ SG_ 328 tcm148_gear "RAM FFF88B80 b4-7; inferred; -> 0x1166F0 -> FFF8A8D5 (1..6, 0xD, 0xE, 0; others hold) -> FFF8A899 (0x08254C gear path, ignition 0x0DE0E0, cruise)";
CM_ SG_ 328 tcm148_b7_bit0 "RAM FFF88B81 b0; read";
CM_ SG_ 328 tcm148_b7_bit1 "RAM FFF88B89 b3; read";
CM_ SG_ 328 tcm148_b7_bit2 "RAM FFF88B89 b2; read";
CM_ SG_ 328 tcm148_b7_bit4 "RAM FFF88B81 b2; read";
CM_ SG_ 328 tcm148_b7_bit5 "RAM FFF88B81 b3; read";
CM_ BO_ 328 "TCM (U0101/U0402 group FFF88DD9; forced missing on MT coding FFF886AB b7); timeout 20 ms; counter byte1 bits0-3 (frozen check)";
CM_ SG_ 329 tcm149_b0 "RAM FFF88B82; read; consumers 0x13741C, 0x165AC4 (cruise)";
CM_ SG_ 329 tcm149_b1_lo "RAM FFF88B88 b4-7; read; b4-6 -> 0x10F464 -> FFF8A88F (0/2/4 blend request; read by torque, ignition, idle, boost)";
CM_ SG_ 329 tcm149_b1_bit4 "RAM FFF88B86 b5; read";
CM_ SG_ 329 tcm149_b1_bit5 "RAM FFF88B86 b4; read";
CM_ SG_ 329 tcm149_b1_bit6 "RAM FFF88E08 b7; read; no reader found";
CM_ SG_ 329 tcm149_b1_bit7 "RAM FFF88E16 b2; read; -> 0x0BE694";
CM_ SG_ 329 tcm149_idle_target "RAM FFF888B2; inferred; minimum idle target in 0x0F222C (B240 = max(B22C, x*1024/25))";
CM_ SG_ 329 tcm149_torque_limit "RAM FFF88DF6; inferred; used by 0x117778 only when FFF88B80 b2 is set, which no variant-1 frame sets; fallback cal 0x572D0 = 0x55";
CM_ SG_ 329 tcm149_b5 "RAM FFF89270; read; -> 0x0EE338";
CM_ SG_ 329 tcm149_word "RAM FFF8924E; read; -> 0x13B308";
CM_ SG_ 329 tcm149_b7_bit7 "RAM FFF88B89 b6; read";
CM_ BO_ 329 "TCM (FFF88DD9); timeout 20 ms";
CM_ SG_ 338 bcm152_b1_bit0 "RAM FFF88E15 b2; read; 0x11AC8C -> FFF8A8A0 b4";
CM_ SG_ 338 bcm152_b1_bit1 "RAM FFF88E15 b3; read; 0x11AD44 -> FFF8A8A0 b3";
CM_ SG_ 338 bcm152_b1_bit2 "RAM FFF8069E b0; read; 0x11BEDC";
CM_ SG_ 338 bcm152_b1_bit3 "RAM FFF8069E b1; read; 0x11B138 -> FFF8A8A0 b2; 0x11BEDC -> A8A0 b1";
CM_ SG_ 338 bcm152_counter "RAM FFF888C7; read; frozen-counter check 0x0687A8";
CM_ SG_ 338 bcm152_b6_bit0 "RAM FFF88E15 b1; read; SI-Drive enable term in 0x11A8B0";
CM_ SG_ 338 bcm152_b6_bit2 "RAM FFF88BA2 b2; read";
CM_ SG_ 338 bcm152_b6_bit3 "RAM FFF88E09 b6; read";
CM_ SG_ 338 bcm152_b6_bit4 "RAM FFF88BA1 b0; read";
CM_ SG_ 338 bcm152_b6_bit5 "RAM FFF88E09 b5; read; 0x11BDD4 -> FFF8A8A3 b3";
CM_ SG_ 338 bcm152_b6_hi "RAM FFF88DFA; read; 0x11BD6C -> FFF8A8A3 b4";
CM_ SG_ 338 bcm152_b7_bit1 "RAM FFF88BA1 b6; read";
CM_ SG_ 338 bcm152_b7_bit2 "RAM FFF88E15 b4; read; idle air adder B1C4 (cal 0x25A72) in 0x0ECAE0";
CM_ SG_ 338 bcm152_b7_bit3 "RAM FFF88BA1 b5; read; idle air adder B1B6 (cal 0x25A62) in 0x0ECAE0";
CM_ SG_ 338 bcm152_b7_bit4 "RAM FFF88BA1 b4; read";
CM_ SG_ 338 bcm152_b7_bit5 "RAM FFF88E15 b0; read";
CM_ SG_ 338 bcm152_b7_bit6 "RAM FFF88E15 b7; read";
CM_ SG_ 338 bcm152_b7_bit7 "RAM FFF88E09 b3; read";
CM_ BO_ 338 "BCM (FFF88DDA; U0140/U0422 disabled in this ROM); timeout 30 ms; counter byte1 bits4-7";
CM_ SG_ 346 m15a_counter "RAM FFF89061; read; frozen check 0x07B208 -> FFF88DD4 b7";
CM_ SG_ 346 can_restart_req "RAM FFF89066 b0; read; CAN restart (start-state 5); many readers (0x06A064, 0x06A166, fuel, ignition)";
CM_ SG_ 346 m15a_b2_bit2 "RAM FFF89066 b2; read";
CM_ SG_ 346 engine_stop_code "RAM FFF89052 b0-3; read; 0x115E08: FFF8A8C5 = 10 when nibble = 1010b -> 0x0827B2 (A6E7 = 3 mode)";
CM_ SG_ 346 m15a_b7 "RAM FFF89069 b0-2; read; no reader found";
CM_ BO_ 346 "unknown (monitored only when FFF811E3 = 0xA5; no DTC); timeout 30 ms; counter byte0 bits0-3";
CM_ SG_ 353 m161_torque "RAM FFF88BAE; inferred; -> 0x10E640 -> FFF8B3F8 (x*8-64000, floor 16000 = 0 Nm) -> cruise 0x16557C/0x1663AC, 0x18AFC4";
CM_ SG_ 353 m161_b2 "RAM FFF88BAD b0,b1,b3-6 / FFF88BB2 b1,b2; read; cruise flags (0x1196E0, 0x119624, 0x119CCC, 0x119CDC, 0x119DE4, 0x119EF8)";
CM_ SG_ 353 m161_b3 "RAM FFF88BB0; read; 0x118234 -> FFF8A8EE, 0x119624/0x1196E0 -> FFF8A8A4 b1/b2";
CM_ SG_ 353 m161_b5_bit2 "RAM FFF88BB2 b0; read";
CM_ SG_ 353 m161_counter "RAM FFF88BB3; read";
CM_ SG_ 353 m161_switch_code "RAM FFF89246 b0-2; read; 0x10F504 -> FFF8A895 = CAN cruise switch code (used when FFF811E1 b4 and cal 0x36584 = 1)";
CM_ SG_ 353 m161_b6_bit3 "RAM FFF89246 b3; read";
CM_ SG_ 353 m161_checksum "RAM FFF88BB1; read";
CM_ BO_ 353 "unknown driver-assist/cruise unit (inferred); gated by FFF811E1 b4 (meter option); group FFF88DD4 b4/b5/b6, no DTC; timeout 60 ms; counter byte5 bits4-6; checksum byte7 = (sum bytes0..6 + cal 0x579A6 (0)) mod 256 (0x07B03A)";
CM_ SG_ 392 m188_counter "RAM FFF88BAC; read; frozen-counter check 0x068D2E -> FFF8A8A8 b6";
CM_ SG_ 392 m188_code "RAM FFF88BAB b0-2; read; -> 0x1106D0 -> FFF8A89D (b0 + 2*b1 + 4*b2, 0 if b1 and b2) -> 0x11A060: FFF8A8A1 b3 = (code 5 for cal 0x35A94 = 70 passes)";
CM_ BO_ 392 "unknown (own group FFF8A8A8 b6/b7, no DTC); timeout 40 ms; counter byte2 bits1-3";
CM_ SG_ 640 ac280_b0_bit0 "RAM FFF88E17 b0; inferred; -> 0x1195AC (with FFF8A297 b2) -> FFF88B8B b0 = A/C request input of 0x080088 / 0x121B90 (inferred)";
CM_ SG_ 640 ac280_b0_code "RAM FFF88B8B b1-3; read; -> 0x114760 -> FFF8A8BF (0..7) -> idle 0x0EE338, 0x13741C; 0x11B090 -> FFF8A8A0 b0";
CM_ SG_ 640 ac280_counter "RAM FFF88B92; read; frozen-counter check 0x068556";
CM_ SG_ 640 ac280_b1_bit7 "RAM FFF88B8C b7; read; -> 0x111AB8";
CM_ SG_ 640 ac280_b2_bit7 "RAM FFF88B8E b1; read; FFF88B8E is read by 0x0EE338, 0x0F7618, 0x1CFD2E (bit not separated)";
CM_ SG_ 640 ac280_b3 "RAM FFF88B8F; read; radiator fan duty table input 05C998 (0x0F70B4, fan module 0x0F7618, off in stock)";
CM_ SG_ 640 ac280_b4_lo "RAM FFF88B90; read; -> 0x116994 -> FFF8A8D9 (no reader)";
CM_ SG_ 640 ac280_b4_hi "RAM FFF88B8D b5-7; read; -> 0x10E8C4 -> FFF8A889 -> 0x10E9C0 -> FFF8A88A (0..6) -> idle 0x0EE338 / 0x10EA40";
CM_ SG_ 640 ac280_b5 "RAM FFF88B91; inferred; FFF8A8C6 = cal 0x3555C (121) x / 100, cap 128 (0x115F80) -> idle, torque 0x0BE694, 0x080088";
CM_ SG_ 640 ac280_b6_bit0 "RAM FFF88B8E b0; read; forces FFF8A8C6 = cal 0x35A85; set to 1 on frame loss";
CM_ BO_ 640 "unknown, A/C-related (own group FFF88BF9 b6/b7 -> FFF88CE4 b7, no DTC; recovers after 5 good frames); timeout 30 ms; counter byte1 bits0-3";
CM_ SG_ 642 meter_word "RAM FFF88E04; read; -> 0x1108B8 -> FFF8B43C (0x06C336, SSM)";
CM_ SG_ 642 meter_b1_bit3 "RAM FFF88BA8 b0; read";
CM_ SG_ 642 meter_counter "RAM FFF88DE8; read";
CM_ SG_ 642 meter_b3 "RAM FFF88BAA; read; fan table select 05C9BC/05C9B0 (cal 0x342EC = 148), torque 0x0BE694, 0x09621E, 0x0F7618";
CM_ SG_ 642 si_drive_b3 "RAM FFF88BA7 b7; read; SI-Drive: 0x115D10 -> FFF8A8C4 -> FFF8A8C1";
CM_ SG_ 642 m282_b5_bit4 "RAM FFF88BA8 b2; read; 0x11C330 -> FFF8A8A5 b3";
CM_ SG_ 642 m282_b5_bit5 "RAM FFF88BA8 b1; read; 0x11C330";
CM_ SG_ 642 si_drive_b6 "RAM FFF88BA7 b5; read";
CM_ SG_ 642 si_drive_b7 "RAM FFF88BA7 b6; read";
CM_ SG_ 642 meter_code "RAM FFF88BA9 b4-7; read; 0x10F344 -> FFF8A88C (0..15, market/units code, cruise tables)";
CM_ SG_ 642 cruise_option "RAM FFF88BA7 b0; read; 0x119B54 -> FFF811E1 b4 after cal 0x35BEA = 10 passes";
CM_ SG_ 642 m282_b7_bit1 "RAM FFF88BA7 b1; read; 0x119A20 -> FFF811E1 b2/b3";
CM_ SG_ 642 m282_b7_bit4 "RAM FFF88BA7 b3; read; 0x115E30 -> FFF811E3 = 0xA5 (clear) / 0x5A (set) after 10 passes";
CM_ SG_ 642 m282_b7_bit7 "RAM FFF88BA7 b4; read; 0x11C4C8 -> FFF811DF b2/b5 (speed scale select)";
CM_ BO_ 642 "combination meter (FFF88DD4 b2/b3 = U0155/U0423); timeout 60 ms; counter byte1 bits4-7";
CM_ SG_ 864 fuel_flow "RAM FFF8B43A; read/inferred; 1000 x cal 0x35B32 (49917) x C230 x rpm_raw x 2.6375e-11/60 x cal 0x35B34/32768, C230 = sum of the 8 injector pulse words x 0.8 / 4; 0 when engine not rotating; clamp 65535";
CM_ SG_ 864 oil_temp "RAM FFF8A8E3 = FFF88A9D - 10; read; Engine oil temperature (88A9D = degC+50); 40 (0 degC) when FFF88E2B b5 (oil sensor fault)";
CM_ SG_ 864 coolant_temp "RAM FFF8A8F1 = FFF8869E - 10; read; Coolant temperature (Coolant Temp Sensor Scaling, degC+50); 0xFF when FFF88E28 b1 (sensor fault)";
CM_ SG_ 864 map "RAM FFF8A8D7 = filt(FFF8869C >> 9); read/inferred; Manifold pressure, 2 kPa/bit, first-order filtered (cal 0x3650A); 7 when FFF88E28 b3 (MAP fault); init 0x33";
CM_ SG_ 864 flag_888A7b1 "RAM FFF888A7 b1; unknown; Output of 0x11A9D8 (pedal, speed, drive mode, rpm inputs)";
CM_ SG_ 864 drive_mode_req_bits "RAM FFF8A8AF b1-3; read; b1/b2 = A8C2 code (as 0x144), b3 = A8C0 in {2..5}";
CM_ SG_ 864 cruise_lamp_main "RAM FFF888A1 b6; inferred; Cruise indicator (state 0xA0 standby, blink timer cal 0x409BC)";
CM_ SG_ 864 cruise_lamp_set "RAM FFF888A1 b7; inferred; Cruise SET indicator (controlling, cal 0x409CC)";
CM_ SG_ 864 engine_warm_latch "RAM FFF8A8AF b6; read/inferred; Latched once FFF88A44 > cal 0x35BDA";
CM_ SG_ 864 flag_ACECb4 "RAM FFF8ACEC b4; unknown; Module 0x19818C";
CM_ SG_ 864 flag_88E14b0 "RAM FFF88E14 b0; read; 1 with MT coding, else coolant FFF8CD65 < cal 0x35518 (0)";
CM_ SG_ 864 elec_load_flag "RAM FFF8A8B0 b1; inferred; 0 when A290 b5 clear and load word B458 (CAN 0x370) below cal 0x35AA0 (hyst 0x35AA2)";
CM_ SG_ 864 flag_88E14b4 "RAM FFF88E14 b4; unknown; 0x11C440(coolant, MT coding, AC78, 88EA2 b3, 88B8C b7)";
CM_ SG_ 864 flag_8889Eb5 "RAM FFF8889E b5; unknown; 0x11B4A8(engine state 906B, coolant at start 88A46, coolant)";
CM_ SG_ 864 rad_fan_1 "RAM FFF8A8B3 b0 <- FFF9981C b0; read; Radiator fan stage >= 1 output (cal 0x57584 b3 = 0)";
CM_ SG_ 864 rad_fan_2 "RAM FFF8A8B3 b1 <- FFF9981C b4; read; Radiator fan stage 2 output (port PF6)";
CM_ SG_ 864 ac_switch_PA8 "RAM FFF8A29C b5; read; Discrete pin PA8 (A/C-load switch, Phase 16)";
CM_ SG_ 864 ac_request "RAM FFF88BC6 b0; read; A/C request (pin PH4 or CAN)";
CM_ SG_ 864 cruise_set_speed "RAM FFF8AB65; read; Cruise set speed B9FC (km/h x 128) rounded; x1000/1609 (mph) when A8A7 b0 (mph meter); 0 when main switch off";
CM_ BO_ 864 "period 50 ms";
CM_ SG_ 865 gear_calc "RAM FFF8A8B1 b0-2 <- FFF8A8B7; inferred; Gear 1..6 binary from 0x114230 (20 ms gear logic; shift-indicator gear, inferred)";
CM_ SG_ 865 flag_88E13b1 "RAM FFF88E13 b1; read; 0 on this ROM (cal 0x57585 b3 = 0 holds init)";
CM_ SG_ 865 maint_flag_811E0 "RAM FFF811E0 b0; unknown; Backup-RAM flag from 0x11BB08 (counters 1148C/1148E, A8D1); maintenance-type reminder (guess)";
CM_ SG_ 865 flag_88E13b2 "RAM FFF88E13 b2; read; 0 on this ROM (cal 0x57585 b3 = 0)";
CM_ SG_ 865 coding_bits "RAM FFF8A8AD b2,b3,b4,b7; read; From cal 0x58B7A -> 0b0001 on this ROM";
CM_ SG_ 865 mil_code "RAM FFF8A8C9; read/inferred; 88E69 b1/b2 -> 4 (flash phase on), 1 (lamp off / flash off phase), 0 (steady on); init 1";
CM_ SG_ 865 booster_pressure_raw "RAM FFF8A8C8 <- hi(FFF88D0C); read/inferred; Brake-booster pressure sensor A/D high byte (Phase 18 D)";
CM_ SG_ 865 baro "RAM FFF8A8D2 = (FFF88A36 x 5 >> 9) - 33; read/inferred; Barometric pressure (88A36, kPa x 256 inferred), clamp 0..255";
CM_ SG_ 865 rolling_counter "RAM FFF8A894; read; 0..cal 0x35B00 (15), +1 per 50 ms";
CM_ SG_ 865 flag_89053b3 "RAM FFF89053 b3; unknown; 0x082800 (engine-state code input, Phase 11 C)";
CM_ SG_ 865 engine_not_rotating "RAM FFF88A2D b0; read; Engine not rotating (Phase 14)";
CM_ SG_ 865 flag_89053b5 "RAM FFF89053 b5; unknown; 0x082674";
CM_ SG_ 865 cruise_flag_A8B2b0 "RAM FFF8A8B2 b0; inferred; Cruise standby branch (0x16DB98)";
CM_ SG_ 865 zero_bytes "RAM -; read; Bytes 5-7 = 0 (cal 0x57584 b4 = 0; else B454 lo/hi, A8E0)";
CM_ BO_ 865 "period 50 ms";
CM_ SG_ 866 battery_current "RAM FFF8B456; read/inferred; (raw - 1875000)/4 of LIN battery-sensor word FFF89074 (I = raw/1000 - 2000 A, from the SOC integrator 0x139798), clamp -125..+125 A; 0xFFFF invalid";
CM_ SG_ 866 lin_value_907A "RAM FFF8A8E1 <- FFF8907A; unknown; LIN battery-sensor 9-bit value, clamp 250, 0xFF invalid (init 120)";
CM_ SG_ 866 battery_soc "RAM FFF8A8DD = FFF8B72C/5; read/inferred; Battery state of charge (B72C = % x 10, 0x139798)";
CM_ SG_ 866 lin_value_89084 "RAM FFF8A8F2 = min(89084,2000)>>3; unknown; LIN battery-sensor value; 0xFF invalid";
CM_ SG_ 866 lin_value_89258 "RAM FFF8A8F4 = min(89258,2000)>>3; unknown; LIN battery-sensor value; 0xFF invalid";
CM_ SG_ 866 lin_value_928E "RAM FFF8A8F3 = min(928E,16000)>>6; unknown; LIN battery-sensor value; 0xFF invalid";
CM_ SG_ 866 lin_fault_flag "RAM FFF88E0E b1; inferred; 89245 b2 or b1 (LIN status) while cal 0x57584 b4 = 0";
CM_ SG_ 866 lin_status_89245b0 "RAM FFF89245 b0; unknown; 0x096740 (LIN status)";
CM_ SG_ 866 lin_flag_88E0Eb2 "RAM FFF88E0E b2; unknown; Set/cleared by the LIN receiver 0x097B06/0x097C12";
CM_ BO_ 866 "period 50 ms";
CM_ SG_ 872 tcm368_b1_bit4 "RAM FFF88B88 b0; read";
CM_ SG_ 872 tcm368_b1_bit5 "RAM FFF88B88 b1; read";
CM_ SG_ 872 tcm368_b1_bit6 "RAM FFF88B89 b0; read; -> 0x10F434 -> FFF8A88E (0..3) -> cruise 0x165AC4/0x167988";
CM_ SG_ 872 tcm368_b1_bit7 "RAM FFF88B89 b1; read; -> FFF8A88E";
CM_ SG_ 872 tcm368_b3 "RAM FFF88B8A; read; no reader found";
CM_ BO_ 872 "TCM (FFF88DD9); timeout 60 ms";
CM_ SG_ 880 m370_word "RAM FFF88BA4; inferred; -> 0x114AD0 -> FFF8B458 (zero when byte3 bit0) = idle air adder (electrical load, inferred) in 0x0ECAE0, 0x0801B8, 0x111AB8";
CM_ SG_ 880 m370_b3_bit0 "RAM FFF88BA3 b0; inferred; invalid flag for the word (inferred)";
CM_ SG_ 880 m370_b3_bit1 "RAM FFF88BA3 b1; read";
CM_ SG_ 880 m370_counter "RAM FFF888CC; read";
CM_ BO_ 880 "unknown (group FFF88DD4 b0/b1, no DTC); timeout 60 ms; counter byte5 bits0-3";
CM_ SG_ 882 m372_counter "RAM FFF88E06; read";
CM_ SG_ 882 m372_code "RAM FFF88E07; read; 0x1137D0 (40 ms) -> 0x118EAC -> FFF8A890..A892, FFF8A8A6 b1-b4 -> 0x128B18";
CM_ BO_ 882 "unknown (group FFF88EDD b0/b1, no DTC; recovers after 5 good frames); timeout 110 ms; counter byte1 bits4-7";
CM_ SG_ 977 ambient_temp_raw "RAM FFF89248; inferred; 0x1FFF = startup/invalid, 0x1FFE = frame lost; filtered FFF8924A (0x071DC6) checked by P0072/P0073 (0x071E14: <3523 -> P0073, >4873 -> P0072)";
CM_ BO_ 977 "combination meter group (counts toward U0155 when cal 0x58EBE = 'Z'); timeout 30 ms";
CM_ SG_ 1632 m660_w0 "RAM FFF88DFC; read; no reader found";
CM_ SG_ 1632 m660_w1 "RAM FFF88DFE; inferred; 0xFFFF = invalid; -> 0x1101B0 -> FFF81494 (DTC record stamp, 0x0A09C6)";
CM_ SG_ 1632 m660_dist "RAM FFF88E00; inferred; 0xFFFFFF = invalid; last valid FFF8900C -> 0x110108 -> FFF8C228 (monotonic, DTC record stamp)";
CM_ BO_ 1632 "BCM group (FFF88DDA; loss counts only with cal 0x57585 b4); timeout 510 ms";
CM_ SG_ 1905 periodic_did "RAM FFF9B869[k + i*0x28]; read";
CM_ SG_ 1905 did_data "RAM 7 byte pointers FFF9B288[did*7+j] (set by 0x2C); read";
CM_ BO_ 1905 "period per request: 100 (slow), 50 (medium), 10 (fast) per periodic DID ms";
CM_ BO_ 2024 "period on request ms";
